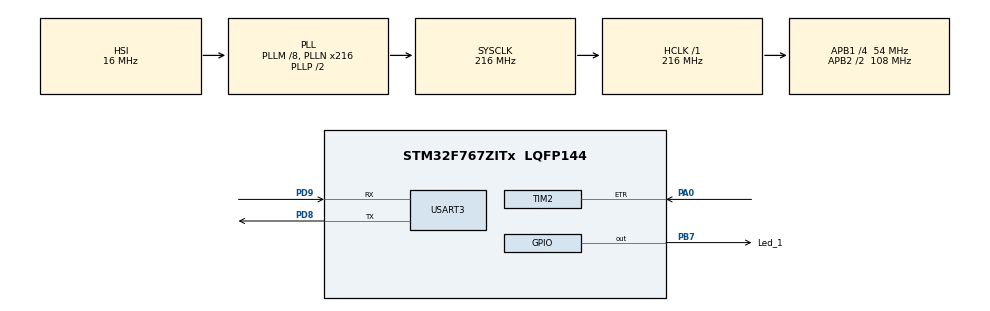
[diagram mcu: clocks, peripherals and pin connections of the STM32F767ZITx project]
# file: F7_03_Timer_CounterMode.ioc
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Mcu.Family=STM32F7
Mcu.Name=STM32F767ZITx
Mcu.Package=LQFP144
NVIC.PriorityGroup=NVIC_PRIORITYGROUP_4
NVIC.TIM2_IRQn=true\:0\:0\:false\:false\:true\:true\:true
PA0/WKUP.Signal=S_TIM2_CH1_ETR
PA13.Mode=Serial_Wire
PA13.Signal=SYS_JTMS-SWDIO
PA14.Mode=Serial_Wire
PA14.Signal=SYS_JTCK-SWCLK
PB7.GPIO_Label=Led_1
PB7.Signal=GPIO_Output
PD8.Mode=Asynchronous
PD8.Signal=USART3_TX
PD9.Mode=Asynchronous
PD9.Signal=USART3_RX
PH0/OSC_IN.Mode=HSE-External-Oscillator
PH0/OSC_IN.Signal=RCC_OSC_IN
PH1/OSC_OUT.Mode=HSE-External-Oscillator
PH1/OSC_OUT.Signal=RCC_OSC_OUT
ProjectManager.HeapSize=0x200
ProjectManager.StackSize=0x400
ProjectManager.TargetToolchain=STM32CubeIDE
RCC.AHBFreq_Value=216000000
RCC.APB1CLKDivider=RCC_HCLK_DIV4
RCC.APB1Freq_Value=54000000
RCC.APB1TimFreq_Value=108000000
RCC.APB2CLKDivider=RCC_HCLK_DIV2
RCC.APB2Freq_Value=108000000
RCC.APB2TimFreq_Value=216000000
RCC.CortexFreq_Value=216000000
RCC.HCLKFreq_Value=216000000
RCC.HSE_VALUE=25000000
RCC.HSI_VALUE=16000000
RCC.LSE_VALUE=32768
RCC.PLLM=8
RCC.PLLN=216
RCC.SYSCLKFreq_VALUE=216000000
RCC.SYSCLKSource=RCC_SYSCLKSOURCE_PLLCLK
RCC.USBFreq_Value=216000000
RCC.VCOOutputFreq_Value=432000000
SH.S_TIM2_CH1_ETR.0=TIM2_ETR,ClockSourceETR_Mode2
TIM2.AutoReloadPreload=TIM_AUTORELOAD_PRELOAD_ENABLE
TIM2.ClockFilter=15
TIM2.Period=20
TIM3.AutoReloadPreload=TIM_AUTORELOAD_PRELOAD_ENABLE
TIM3.Period=20
USART3.VirtualMode-Asynchronous=VM_ASYNC
VP_TIM3_VS_ClockSourceINT.Mode=Internal
board=custom

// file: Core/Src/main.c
/* USER CODE BEGIN Header */
/**
  ******************************************************************************
  * @file           : main.c
  * @brief          : Main program body
  ******************************************************************************
  * @attention
  *
  * Copyright (c) 2022 STMicroelectronics.
  * All rights reserved.
  *
  * This software is licensed under terms that can be found in the LICENSE file
  * in the root directory of this software component.
  * If no LICENSE file comes with this software, it is provided AS-IS.
  *
  ******************************************************************************
  */
/* USER CODE END Header */
#include "main.h"

/* USER CODE BEGIN Includes */
	uint8_t End_msg[35]= "Overflow Reached! Counter Reset!\n\r";
/* USER CODE END Includes */

TIM_HandleTypeDef htim2;
TIM_HandleTypeDef htim3;

UART_HandleTypeDef huart3;

void SystemClock_Config(void);
static void MX_GPIO_Init(void);
static void MX_TIM2_Init(void);
static void MX_USART3_UART_Init(void);
static void MX_TIM3_Init(void);

/* USER CODE BEGIN 0 */
void HAL_TIM_PeriodElapsedCallback(TIM_HandleTypeDef* htim)
{
    HAL_UART_Transmit(&huart3, End_msg, sizeof(End_msg), 100);
}
/* USER CODE END 0 */

int main(void)
{
  /* USER CODE BEGIN 1 */
	uint8_t MSG[20] = {'\0'};
	uint16_t CounterTicks = 0;
  /* USER CODE END 1 */

  /* MCU Configuration--------------------------------------------------------*/

  /* Reset of all peripherals, Initializes the Flash interface and the Systick. */
  HAL_Init();

  /* Configure the system clock */
  SystemClock_Config();

  /* Initialize all configured peripherals */
  MX_GPIO_Init();
  MX_TIM2_Init();
  MX_USART3_UART_Init();
  MX_TIM3_Init();
  /* USER CODE BEGIN 2 */
  HAL_TIM_Base_Start_IT(&htim2);
  /* USER CODE END 2 */

  /* Infinite loop */
  while (1)
  {

    /* USER CODE BEGIN 3 */
      // Read The Counter Ticks Register
      CounterTicks = TIM2->CNT;
      // Print The Ticks Count Via UART1
      sprintf(MSG, "Ticks = %d\n\r", CounterTicks);
      HAL_UART_Transmit(&huart3, MSG, sizeof(MSG), 100);
      HAL_Delay(100);
  }
  /* USER CODE END 3 */
}

void SystemClock_Config(void)
{
  RCC_OscInitTypeDef RCC_OscInitStruct = {0};
  RCC_ClkInitTypeDef RCC_ClkInitStruct = {0};

  /** Configure the main internal regulator output voltage
  */
  __HAL_RCC_PWR_CLK_ENABLE();
  __HAL_PWR_VOLTAGESCALING_CONFIG(PWR_REGULATOR_VOLTAGE_SCALE1);
  /** Initializes the RCC Oscillators according to the specified parameters
  * in the RCC_OscInitTypeDef structure.
  */
  RCC_OscInitStruct.OscillatorType = RCC_OSCILLATORTYPE_HSI;
  RCC_OscInitStruct.HSIState = RCC_HSI_ON;
  RCC_OscInitStruct.HSICalibrationValue = RCC_HSICALIBRATION_DEFAULT;
  RCC_OscInitStruct.PLL.PLLState = RCC_PLL_ON;
  RCC_OscInitStruct.PLL.PLLSource = RCC_PLLSOURCE_HSI;
  RCC_OscInitStruct.PLL.PLLM = 8;
  RCC_OscInitStruct.PLL.PLLN = 216;
  RCC_OscInitStruct.PLL.PLLP = RCC_PLLP_DIV2;
  RCC_OscInitStruct.PLL.PLLQ = 2;
  RCC_OscInitStruct.PLL.PLLR = 2;
  if (HAL_RCC_OscConfig(&RCC_OscInitStruct) != HAL_OK)
  {
    Error_Handler();
  }
  /** Activate the Over-Drive mode
  */
  if (HAL_PWREx_EnableOverDrive() != HAL_OK)
  {
    Error_Handler();
  }
  /** Initializes the CPU, AHB and APB buses clocks
  */
  RCC_ClkInitStruct.ClockType = RCC_CLOCKTYPE_HCLK|RCC_CLOCKTYPE_SYSCLK
                              |RCC_CLOCKTYPE_PCLK1|RCC_CLOCKTYPE_PCLK2;
  RCC_ClkInitStruct.SYSCLKSource = RCC_SYSCLKSOURCE_PLLCLK;
  RCC_ClkInitStruct.AHBCLKDivider = RCC_SYSCLK_DIV1;
  RCC_ClkInitStruct.APB1CLKDivider = RCC_HCLK_DIV4;
  RCC_ClkInitStruct.APB2CLKDivider = RCC_HCLK_DIV2;

  if (HAL_RCC_ClockConfig(&RCC_ClkInitStruct, FLASH_LATENCY_7) != HAL_OK)
  {
    Error_Handler();
  }
}

static void MX_TIM2_Init(void)
{

  TIM_ClockConfigTypeDef sClockSourceConfig = {0};
  TIM_MasterConfigTypeDef sMasterConfig = {0};

  htim2.Instance = TIM2;
  htim2.Init.Prescaler = 0;
  htim2.Init.CounterMode = TIM_COUNTERMODE_UP;
  htim2.Init.Period = 20;
  htim2.Init.ClockDivision = TIM_CLOCKDIVISION_DIV1;
  htim2.Init.AutoReloadPreload = TIM_AUTORELOAD_PRELOAD_ENABLE;
  if (HAL_TIM_Base_Init(&htim2) != HAL_OK)
  {
    Error_Handler();
  }
  sClockSourceConfig.ClockSource = TIM_CLOCKSOURCE_ETRMODE2;
  sClockSourceConfig.ClockPolarity = TIM_CLOCKPOLARITY_NONINVERTED;
  sClockSourceConfig.ClockPrescaler = TIM_CLOCKPRESCALER_DIV1;
  sClockSourceConfig.ClockFilter = 15;
  if (HAL_TIM_ConfigClockSource(&htim2, &sClockSourceConfig) != HAL_OK)
  {
    Error_Handler();
  }
  sMasterConfig.MasterOutputTrigger = TIM_TRGO_RESET;
  sMasterConfig.MasterSlaveMode = TIM_MASTERSLAVEMODE_DISABLE;
  if (HAL_TIMEx_MasterConfigSynchronization(&htim2, &sMasterConfig) != HAL_OK)
  {
    Error_Handler();
  }

}

static void MX_TIM3_Init(void)
{

  TIM_ClockConfigTypeDef sClockSourceConfig = {0};
  TIM_MasterConfigTypeDef sMasterConfig = {0};

  htim3.Instance = TIM3;
  htim3.Init.Prescaler = 0;
  htim3.Init.CounterMode = TIM_COUNTERMODE_UP;
  htim3.Init.Period = 20;
  htim3.Init.ClockDivision = TIM_CLOCKDIVISION_DIV1;
  htim3.Init.AutoReloadPreload = TIM_AUTORELOAD_PRELOAD_ENABLE;
  if (HAL_TIM_Base_Init(&htim3) != HAL_OK)
  {
    Error_Handler();
  }
  sClockSourceConfig.ClockSource = TIM_CLOCKSOURCE_INTERNAL;
  if (HAL_TIM_ConfigClockSource(&htim3, &sClockSourceConfig) != HAL_OK)
  {
    Error_Handler();
  }
  sMasterConfig.MasterOutputTrigger = TIM_TRGO_RESET;
  sMasterConfig.MasterSlaveMode = TIM_MASTERSLAVEMODE_DISABLE;
  if (HAL_TIMEx_MasterConfigSynchronization(&htim3, &sMasterConfig) != HAL_OK)
  {
    Error_Handler();
  }

}

static void MX_USART3_UART_Init(void)
{

  huart3.Instance = USART3;
  huart3.Init.BaudRate = 115200;
  huart3.Init.WordLength = UART_WORDLENGTH_8B;
  huart3.Init.StopBits = UART_STOPBITS_1;
  huart3.Init.Parity = UART_PARITY_NONE;
  huart3.Init.Mode = UART_MODE_TX_RX;
  huart3.Init.HwFlowCtl = UART_HWCONTROL_NONE;
  huart3.Init.OverSampling = UART_OVERSAMPLING_16;
  huart3.Init.OneBitSampling = UART_ONE_BIT_SAMPLE_DISABLE;
  huart3.AdvancedInit.AdvFeatureInit = UART_ADVFEATURE_NO_INIT;
  if (HAL_UART_Init(&huart3) != HAL_OK)
  {
    Error_Handler();
  }

}

static void MX_GPIO_Init(void)
{
  GPIO_InitTypeDef GPIO_InitStruct = {0};

  /* GPIO Ports Clock Enable */
  __HAL_RCC_GPIOH_CLK_ENABLE();
  __HAL_RCC_GPIOA_CLK_ENABLE();
  __HAL_RCC_GPIOD_CLK_ENABLE();
  __HAL_RCC_GPIOB_CLK_ENABLE();

  /*Configure GPIO pin Output Level */
  HAL_GPIO_WritePin(Led_1_GPIO_Port, Led_1_Pin, GPIO_PIN_RESET);

  /*Configure GPIO pin : Led_1_Pin */
  GPIO_InitStruct.Pin = Led_1_Pin;
  GPIO_InitStruct.Mode = GPIO_MODE_OUTPUT_PP;
  GPIO_InitStruct.Pull = GPIO_NOPULL;
  GPIO_InitStruct.Speed = GPIO_SPEED_FREQ_LOW;
  HAL_GPIO_Init(Led_1_GPIO_Port, &GPIO_InitStruct);

}

void Error_Handler(void)
{
  __disable_irq();
  while (1)
  {
  }
}
